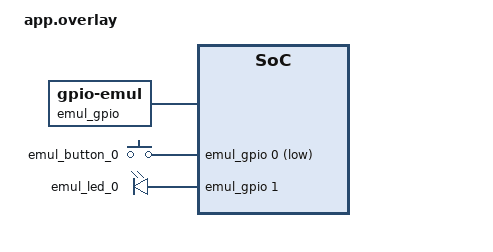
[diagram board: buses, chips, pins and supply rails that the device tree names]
/* Test image overlay for native_sim: button and LED both on the GPIO emulator. */
#include <zephyr/dt-bindings/gpio/gpio.h>
#include <zephyr/dt-bindings/input/input-event-codes.h>

/ {
    emul_gpio: gpio_emul {
        compatible = "zephyr,gpio-emul";
        status = "okay";
        gpio-controller;
        #gpio-cells = <2>;
        ngpios = <4>;
        interrupt-controller;
        #interrupt-cells = <2>;
        rising-edge;
        falling-edge;
        high-level;
        low-level;
    };

    emul_keys {
        compatible = "gpio-keys";
        emul_button_0: emul_button_0 {
            gpios = <&emul_gpio 0 GPIO_ACTIVE_LOW>;
            zephyr,code = <INPUT_KEY_0>;
        };
    };

    emul_leds {
        compatible = "gpio-leds";
        emul_led_0: emul_led_0 {
            gpios = <&emul_gpio 1 GPIO_ACTIVE_HIGH>;
        };
    };

    /* Both aliases move: native_sim's default led0 sits on a GPIO controller
     * this build doesn't enable, so toggling it would crash. */
    aliases {
        sw0 = &emul_button_0;
        led0 = &emul_led_0;
    };
};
